# ESP32S31_RADIO register map
Vendor: Espressif; Series: ESP32-S31; File version: 3.52
Registers are 32-bit, read-write, no defined reset value unless marked. A register's access mark holds for its fields unless they carry their own. Offsets are from the block's base; [hi:lo] are bit positions; {n}, {i} and the like mark numbered series.

## PHY_BB_RECOVERED_GAPS — Sparse BB words absent from the public platform PAC.
Base 0x20107C00
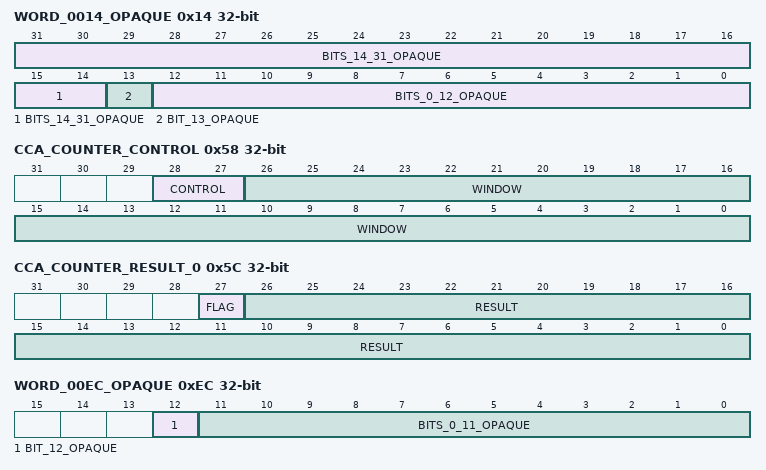
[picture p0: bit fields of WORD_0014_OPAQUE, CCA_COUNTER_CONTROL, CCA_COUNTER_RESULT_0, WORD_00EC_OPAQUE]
0x14 WORD_0014_OPAQUE — Opaque: meaning not established. Complete phy_spur_coef_cfg clears bit 13 through two read-modify-write paths; all hardware field names remain unknown.
  [31:14] BITS_14_31_OPAQUE — Opaque: meaning not established. Observed source use; the individual hardware meaning is unknown.
  [13] BIT_13_OPAQUE — Opaque: meaning not established.
  [12:0] BITS_0_12_OPAQUE — Opaque: meaning not established. Observed source use; the individual hardware meaning is unknown.
0x58 CCA_COUNTER_CONTROL — Project-assigned name. CCA measurement window and control. SOURCE: complete rev0 ROM phy_set_cca_cnt replaces the low 27 bits and optionally sets bits 28:27.
  [28:27] CONTROL — Project-assigned name. Counter control; individual bit roles unknown. SOURCE: complete rev0 ROM phy_set_cca_cnt sets both bits when arg1 is nonzero.
  [26:0] WINDOW — Project-assigned name. Measurement window length; physical units unknown. SOURCE: complete rev0 ROM phy_set_cca_cnt arg0.
0x5C CCA_COUNTER_RESULT_0 access not given — Project-assigned name. First CCA window result and flag. SOURCE: complete rev0 ROM phy_get_cca_cnt copies bits 26:0 to out[0] and returns bit 27.
  [27] FLAG — Project-assigned name. Counter flag returned as 0/1; physical meaning unknown. SOURCE: complete rev0 ROM phy_get_cca_cnt return value.
  [26:0] RESULT — Project-assigned name. First window measurement result. SOURCE: complete rev0 ROM phy_get_cca_cnt out[0].
0x60 CCA_COUNTER_RESULT_1 access not given — Project-assigned name. Second CCA window result. SOURCE: complete rev0 ROM phy_get_cca_cnt copies bits 26:0 to out[1].
  [26:0] RESULT — Project-assigned name. Second window measurement result. SOURCE: complete rev0 ROM phy_get_cca_cnt out[1].
0xE8 WORD_00E8_OPAQUE — Opaque: meaning not established. Complete phy_bb_cfo_cfg reads and replaces this word; individual hardware fields remain unnamed.
  [31:0] BITS_0_31_OPAQUE — Opaque: meaning not established. Observed source use; the individual hardware meaning is unknown.
0xEC WORD_00EC_OPAQUE — Opaque: meaning not established. Complete phy_bb_cfo_cfg replaces this word and independently read-modify-writes bit 12; the hardware field meaning remains unknown.
  [12] BIT_12_OPAQUE — Opaque: meaning not established.
  [11:0] BITS_0_11_OPAQUE — Opaque: meaning not established. Observed source use; the individual hardware meaning is unknown.

## PHY_BRX_RECOVERED_GAPS — Sparse BRX words absent from the public platform PAC.
Base 0x20108000
0x50 WORD_0050_OPAQUE — Opaque: meaning not established. Complete phy_freq_correct read-modify-writes this word; individual fields remain unnamed.
  [14:0] BITS_0_14_OPAQUE — Opaque: meaning not established. Observed source use; the individual hardware meaning is unknown.

## MODEM_ETM — ESP32-S31 modem event-task matrix at MODEM_BASE + 0x8800, shared by the IEEE 802.15.4 and Bluetooth lifecycles. The public IEEE 802.15.4 driver names the channel-enable, set and clear words and the per-channel event/task pair at an eight-byte stride, and programs channels zero and one; the BTDM runtime programs channels four through seven through the same words. Channel bits and identifiers without a reviewed user remain absent and no reset values are claimed.
Base 0x20108800
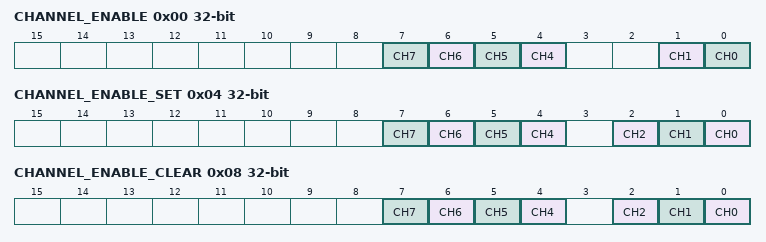
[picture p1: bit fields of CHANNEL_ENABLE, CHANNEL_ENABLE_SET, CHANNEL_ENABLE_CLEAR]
0x00 CHANNEL_ENABLE ro — Project-assigned name. Channel-enable status word. The IEEE 802.15.4 driver reads it to decide whether a channel must be disabled; the BTDM runtime reads the complete word.
  [n] CH{n} (n=4..7) — Channel {n} is enabled.
  [1] CH1 — Channel 1 is enabled.
  [0] CH0 — Channel 0 is enabled.
0x04 CHANNEL_ENABLE_SET wo — Project-assigned name. Channel-enable set word. Its fields are write-trigger: writing 1 enables that channel and writing 0 has no effect, as in the ESP32-S31 SoC ETM of identical layout. This semantics is not yet verified on the modem ETM hardware. The IEEE 802.15.4 driver writes the word back after reading it with the selected channel bit added; the BTDM runtime writes complete channel images.
  [n] CH{n} (n=4..7) — Writing 1 enables channel {n}.
  [2] CH2 — Writing 1 enables channel 2.
  [1] CH1 — Writing 1 enables channel 1.
  [0] CH0 — Writing 1 enables channel 0.
0x08 CHANNEL_ENABLE_CLEAR wo — Project-assigned name. Channel-enable clear word. Its fields are write-trigger: writing 1 disables that channel and writing 0 has no effect, as in the ESP32-S31 SoC ETM of identical layout. This semantics is not yet verified on the modem ETM hardware. The IEEE 802.15.4 driver writes the word back after reading it with the selected channel bit added; the BTDM runtime writes complete single-channel images.
  [n] CH{n} (n=4..7) — Writing 1 disables channel {n}.
  [2] CH2 — Project-assigned name. Writing 1 disables channel 2.
  [1] CH1 — Writing 1 disables channel 1.
  [0] CH0 — Writing 1 disables channel 0.
{0xC+8i} CH{i}_EVENT (i=0..7) — Project-assigned name. Complete event identifier monitored by the selected channel.
  [31:0] ID — Event identifier written as a complete word.
    79=IEEE802154_TIMER1_OVERFLOW; 80=IEEE802154_TIMER0_OVERFLOW
{0x10+8i} CH{i}_TASK (i=0..7) — Project-assigned name. Complete task identifier triggered when the selected channel's event occurs.
  [31:0] ID — Task identifier written as a complete word.
    84=IEEE802154_ED_TRIG_TX; 85=IEEE802154_RX_START; 88=IEEE802154_TX_START
